# ESP32-S2 register map
Vendor: ESPRESSIF SYSTEMS (SHANGHAI) CO., LTD.; Series: ESP32 S-Series; File version: 20
CPU: Xtensa LX7 r0p0, little endian, no MPU, no FPU, 0 interrupt priority bits
Address unit: 32 bits
Registers are 32-bit, read-write, reset 0x0 unless marked. A register's access mark holds for its fields unless they carry their own. Offsets are from the block's base; [hi:lo] are bit positions; {n}, {i} and the like mark numbered series.

## SHA — SHA (Secure Hash Algorithm) Accelerator
Base 0x6003B000
0x00 MODE — Defines the algorithm of SHA accelerator
  [2:0] MODE — Defines the SHA algorithm.
0x04 T_STRING — String content register for calculating initial Hash Value (only effective for SHA-512/t)
  [31:0] T_STRING — Defines t_string for calculating the initial Hash value for SHA-512/t.
0x08 T_LENGTH — String length register for calculating initial Hash Value (only effective for SHA-512/t)
  [5:0] T_LENGTH — Defines t_length for calculating the initial Hash value for SHA-512/t.
0x0C DMA_BLOCK_NUM — Block number register (only effective for DMA-SHA)
  [5:0] DMA_BLOCK_NUM — Defines the DMA-SHA block number.
0x10 START wo — Starts the SHA accelerator for Typical SHA operation
  [0] START — Write 1 to start Typical SHA calculation.
0x14 CONTINUE_OP wo — Continues SHA operation (only effective in Typical SHA mode)
  [0] CONTINUE_OP — Write 1 to continue Typical SHA calculation.
0x18 BUSY ro — Indicates if SHA Accelerator is busy or not
  [0] STATE — Indicates the states of SHA accelerator. 1'h0: idle 1'h1: busy
0x1C DMA_START wo — Starts the SHA accelerator for DMA-SHA operation
  [0] DMA_START — Write 1 to start DMA-SHA calculation.
0x20 DMA_CONTINUE wo — Continues SHA operation (only effective in DMA-SHA mode)
  [0] DMA_CONTINUE — Write 1 to continue DMA-SHA calculation.
0x24 INT_CLEAR wo — DMA-SHA interrupt clear register
  [0] CLEAR_INTERRUPT — Clears DMA-SHA interrupt.
0x28 INT_ENA — DMA-SHA interrupt enable register
  [0] INTERRUPT_ENA — Enables DMA-SHA interrupt.
0x2C DATE reset 0x20190402 — Version control register
  [29:0] DATE — Version control register.
{0x40+4i} H_{i} (i=0..15) — Hash value
  [31:0] H — Stores the %sth 32-bit piece of the Hash value.
{0x80+4i} M_{i} (i=0..31) — Message
  [31:0] M — Stores the %sth 32-bit piece of the message.

## SYSCON — SYSCON Peripheral
Base 0x3F426000
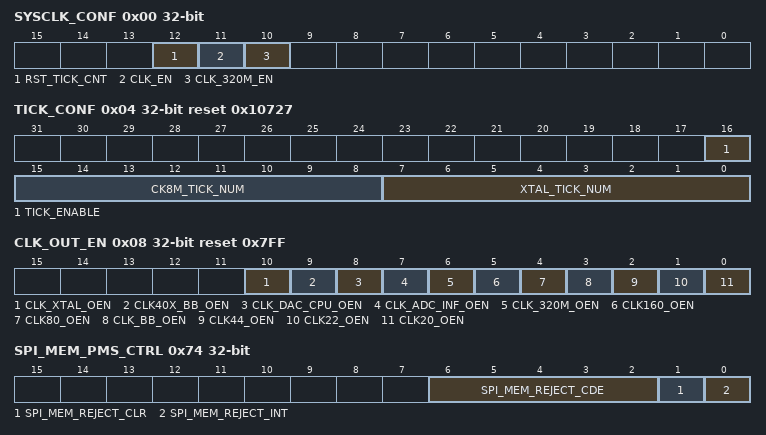
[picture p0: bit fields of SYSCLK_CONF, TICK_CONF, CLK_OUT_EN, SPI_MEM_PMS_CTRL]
0x00 SYSCLK_CONF
  [12] RST_TICK_CNT, [11] CLK_EN, [10] CLK_320M_EN
0x04 TICK_CONF reset 0x10727
  [16] TICK_ENABLE, [15:8] CK8M_TICK_NUM, [7:0] XTAL_TICK_NUM
0x08 CLK_OUT_EN reset 0x7FF
  [10] CLK_XTAL_OEN, [9] CLK40X_BB_OEN, [8] CLK_DAC_CPU_OEN, [7] CLK_ADC_INF_OEN, [6] CLK_320M_OEN, [5] CLK160_OEN, [4] CLK80_OEN, [3] CLK_BB_OEN, [2] CLK44_OEN, [1] CLK22_OEN, [0] CLK20_OEN
0x0C HOST_INF_SEL
  [7:0] PERI_IO_SWAP
0x10 EXT_MEM_PMS_LOCK
  [0] EXT_MEM_PMS_LOCK
{0x14+4i} FLASH_ACE{i}_ATTR reset 0x7 (i=0..3)
  [2:0] FLASH_ACE{i}_ATTR
0x24 FLASH_ACE0_ADDR
  [31:0] S, [?] FLASH_ACE0_ADDR
0x28 FLASH_ACE1_ADDR reset 0x10000000
  [31:0] S, [?] FLASH_ACE1_ADDR
0x2C FLASH_ACE2_ADDR reset 0x20000000
  [31:0] S, [?] FLASH_ACE2_ADDR
0x30 FLASH_ACE3_ADDR reset 0x30000000
  [31:0] S, [?] FLASH_ACE3_ADDR
{0x34+4i} FLASH_ACE{i}_SIZE reset 0x1000 (i=0..3)
  [15:0] FLASH_ACE{i}_SIZE
{0x44+4i} SRAM_ACE{i}_ATTR reset 0x7 (i=0..3)
  [2:0] SRAM_ACE{i}_ATTR
0x54 SRAM_ACE0_ADDR
  [31:0] S, [?] SRAM_ACE0_ADDR
0x58 SRAM_ACE1_ADDR reset 0x10000000
  [31:0] S, [?] SRAM_ACE1_ADDR
0x5C SRAM_ACE2_ADDR reset 0x20000000
  [31:0] S, [?] SRAM_ACE2_ADDR
0x60 SRAM_ACE3_ADDR reset 0x30000000
  [31:0] S, [?] SRAM_ACE3_ADDR
{0x64+4i} SRAM_ACE{i}_SIZE reset 0x1000 (i=0..3)
  [15:0] SRAM_ACE{i}_SIZE
0x74 SPI_MEM_PMS_CTRL access per field
  [6:2] SPI_MEM_REJECT_CDE ro, [1] SPI_MEM_REJECT_CLR wo, [0] SPI_MEM_REJECT_INT ro
0x78 SPI_MEM_REJECT_ADDR ro
0x7C SDIO_CTRL
  [0] SDIO_WIN_ACCESS_EN
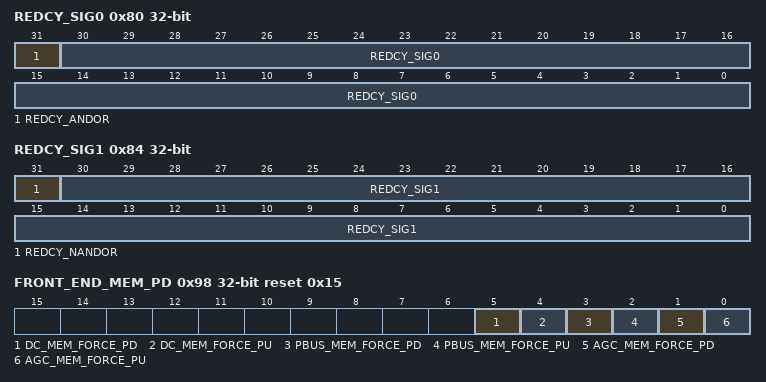
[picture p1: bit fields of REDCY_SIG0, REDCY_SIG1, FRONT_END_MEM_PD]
0x80 REDCY_SIG0 access per field
  [31] REDCY_ANDOR ro, [30:0] REDCY_SIG0 rw
0x84 REDCY_SIG1 access per field
  [31] REDCY_NANDOR ro, [30:0] REDCY_SIG1 rw
0x88 WIFI_BB_CFG
0x8C WIFI_BB_CFG_2
0x90 WIFI_CLK_EN reset 0xFFFCE030
0x94 WIFI_RST_EN reset 0xFFFCE030
  [13:11] DPORT_WIFI_CLK_BT_EN, [31:0] WIFI_RST, [31:0] DPORT_WIFI_CLK_EN, [8:0] DPORT_WIFI_CLK_WIFI_EN, [0] DPORT_WIFI_CLK_WIFI_BT_COMMON, [31:0] DPORT_WIFI_RST
0x98 FRONT_END_MEM_PD reset 0x15
  [5] DC_MEM_FORCE_PD, [4] DC_MEM_FORCE_PU, [3] PBUS_MEM_FORCE_PD, [2] PBUS_MEM_FORCE_PU, [1] AGC_MEM_FORCE_PD, [0] AGC_MEM_FORCE_PU
0x3FC DATE reset 0x1907010
